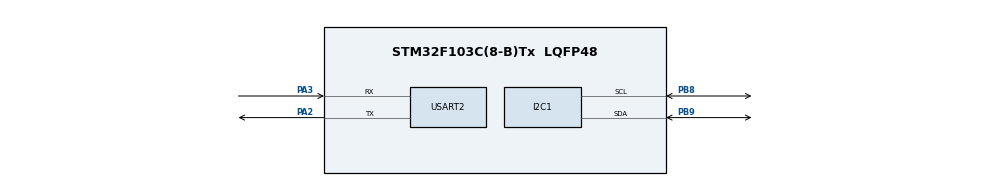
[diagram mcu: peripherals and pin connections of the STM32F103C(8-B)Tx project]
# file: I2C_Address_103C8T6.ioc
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Mcu.Family=STM32F1
Mcu.Name=STM32F103C(8-B)Tx
Mcu.Package=LQFP48
NVIC.PriorityGroup=NVIC_PRIORITYGROUP_4
PA13.Mode=Serial_Wire
PA13.Signal=SYS_JTMS-SWDIO
PA14.Mode=Serial_Wire
PA14.Signal=SYS_JTCK-SWCLK
PA2.Mode=Asynchronous
PA2.Signal=USART2_TX
PA3.Mode=Asynchronous
PA3.Signal=USART2_RX
PB8.Mode=I2C
PB8.Signal=I2C1_SCL
PB9.Mode=I2C
PB9.Signal=I2C1_SDA
PC14-OSC32_IN.Mode=LSE-External-Oscillator
PC14-OSC32_IN.Signal=RCC_OSC32_IN
PC15-OSC32_OUT.Mode=LSE-External-Oscillator
PC15-OSC32_OUT.Signal=RCC_OSC32_OUT
PD0-OSC_IN.Mode=HSE-External-Oscillator
PD0-OSC_IN.Signal=RCC_OSC_IN
PD1-OSC_OUT.Mode=HSE-External-Oscillator
PD1-OSC_OUT.Signal=RCC_OSC_OUT
ProjectManager.HeapSize=0x200
ProjectManager.StackSize=0x400
ProjectManager.TargetToolchain=STM32CubeIDE
RCC.APB1Freq_Value=8000000
RCC.APB2Freq_Value=8000000
USART2.VirtualMode=VM_ASYNC
board=custom

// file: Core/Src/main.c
/* USER CODE BEGIN Header */
/**
 ******************************************************************************
 * @file           : main.c
 * @brief          : Main program body
 ******************************************************************************
 * @attention
 *
 * Copyright (c) 2025 STMicroelectronics.
 * All rights reserved.
 *
 * This software is licensed under terms that can be found in the LICENSE file
 * in the root directory of this software component.
 * If no LICENSE file comes with this software, it is provided AS-IS.
 *
 ******************************************************************************
 */
/* USER CODE END Header */
#include "main.h"

/* USER CODE BEGIN Includes */
#include<string.h>
#include<stdio.h>
/* USER CODE END Includes */

I2C_HandleTypeDef hi2c1;

UART_HandleTypeDef huart2;

void SystemClock_Config(void);
static void MX_GPIO_Init(void);
static void MX_I2C1_Init(void);
static void MX_USART2_UART_Init(void);

/* USER CODE BEGIN 0 */
void I2C_Scan_UART(void) {
	char msg[40];

	HAL_UART_Transmit(&huart2, (uint8_t*) "\r\n--- I2C SCAN START ---\r\n", 26,
			100);

	for (uint8_t addr = 1; addr < 127; addr++) {
		if (HAL_I2C_IsDeviceReady(&hi2c1, addr << 1, 1, 10) == HAL_OK) {
			sprintf(msg, "FOUND DEVICE AT: 0x%02X\r\n", addr);
			HAL_UART_Transmit(&huart2, (uint8_t*) msg, strlen(msg), 100);
		}
	}

	HAL_UART_Transmit(&huart2, (uint8_t*) "--- I2C SCAN DONE ---\r\n", 24, 100);
}

/* USER CODE END 0 */

int main(void) {

	/* MCU Configuration--------------------------------------------------------*/

	/* Reset of all peripherals, Initializes the Flash interface and the Systick. */
	HAL_Init();

	/* Configure the system clock */
	SystemClock_Config();

	/* Initialize all configured peripherals */
	MX_GPIO_Init();
	MX_I2C1_Init();
	MX_USART2_UART_Init();
	/* USER CODE BEGIN 2 */
	I2C_Scan_UART();
	/* USER CODE END 2 */

	/* Infinite loop */
	while (1) {

	}
}

void SystemClock_Config(void) {
	RCC_OscInitTypeDef RCC_OscInitStruct = { 0 };
	RCC_ClkInitTypeDef RCC_ClkInitStruct = { 0 };

	/** Initializes the RCC Oscillators according to the specified parameters
	 * in the RCC_OscInitTypeDef structure.
	 */
	RCC_OscInitStruct.OscillatorType = RCC_OSCILLATORTYPE_HSI;
	RCC_OscInitStruct.HSIState = RCC_HSI_ON;
	RCC_OscInitStruct.HSICalibrationValue = RCC_HSICALIBRATION_DEFAULT;
	RCC_OscInitStruct.PLL.PLLState = RCC_PLL_NONE;
	if (HAL_RCC_OscConfig(&RCC_OscInitStruct) != HAL_OK) {
		Error_Handler();
	}

	/** Initializes the CPU, AHB and APB buses clocks
	 */
	RCC_ClkInitStruct.ClockType = RCC_CLOCKTYPE_HCLK | RCC_CLOCKTYPE_SYSCLK
			| RCC_CLOCKTYPE_PCLK1 | RCC_CLOCKTYPE_PCLK2;
	RCC_ClkInitStruct.SYSCLKSource = RCC_SYSCLKSOURCE_HSI;
	RCC_ClkInitStruct.AHBCLKDivider = RCC_SYSCLK_DIV1;
	RCC_ClkInitStruct.APB1CLKDivider = RCC_HCLK_DIV1;
	RCC_ClkInitStruct.APB2CLKDivider = RCC_HCLK_DIV1;

	if (HAL_RCC_ClockConfig(&RCC_ClkInitStruct, FLASH_LATENCY_0) != HAL_OK) {
		Error_Handler();
	}
}

static void MX_I2C1_Init(void) {

	hi2c1.Instance = I2C1;
	hi2c1.Init.ClockSpeed = 100000;
	hi2c1.Init.DutyCycle = I2C_DUTYCYCLE_2;
	hi2c1.Init.OwnAddress1 = 0;
	hi2c1.Init.AddressingMode = I2C_ADDRESSINGMODE_7BIT;
	hi2c1.Init.DualAddressMode = I2C_DUALADDRESS_DISABLE;
	hi2c1.Init.OwnAddress2 = 0;
	hi2c1.Init.GeneralCallMode = I2C_GENERALCALL_DISABLE;
	hi2c1.Init.NoStretchMode = I2C_NOSTRETCH_DISABLE;
	if (HAL_I2C_Init(&hi2c1) != HAL_OK) {
		Error_Handler();
	}

}

static void MX_USART2_UART_Init(void) {

	huart2.Instance = USART2;
	huart2.Init.BaudRate = 115200;
	huart2.Init.WordLength = UART_WORDLENGTH_8B;
	huart2.Init.StopBits = UART_STOPBITS_1;
	huart2.Init.Parity = UART_PARITY_NONE;
	huart2.Init.Mode = UART_MODE_TX_RX;
	huart2.Init.HwFlowCtl = UART_HWCONTROL_NONE;
	huart2.Init.OverSampling = UART_OVERSAMPLING_16;
	if (HAL_UART_Init(&huart2) != HAL_OK) {
		Error_Handler();
	}

}

static void MX_GPIO_Init(void) {

	/* GPIO Ports Clock Enable */
	__HAL_RCC_GPIOC_CLK_ENABLE();
	__HAL_RCC_GPIOD_CLK_ENABLE();
	__HAL_RCC_GPIOA_CLK_ENABLE();
	__HAL_RCC_GPIOB_CLK_ENABLE();

}

void Error_Handler(void) {
	__disable_irq();
	while (1) {
	}
}
